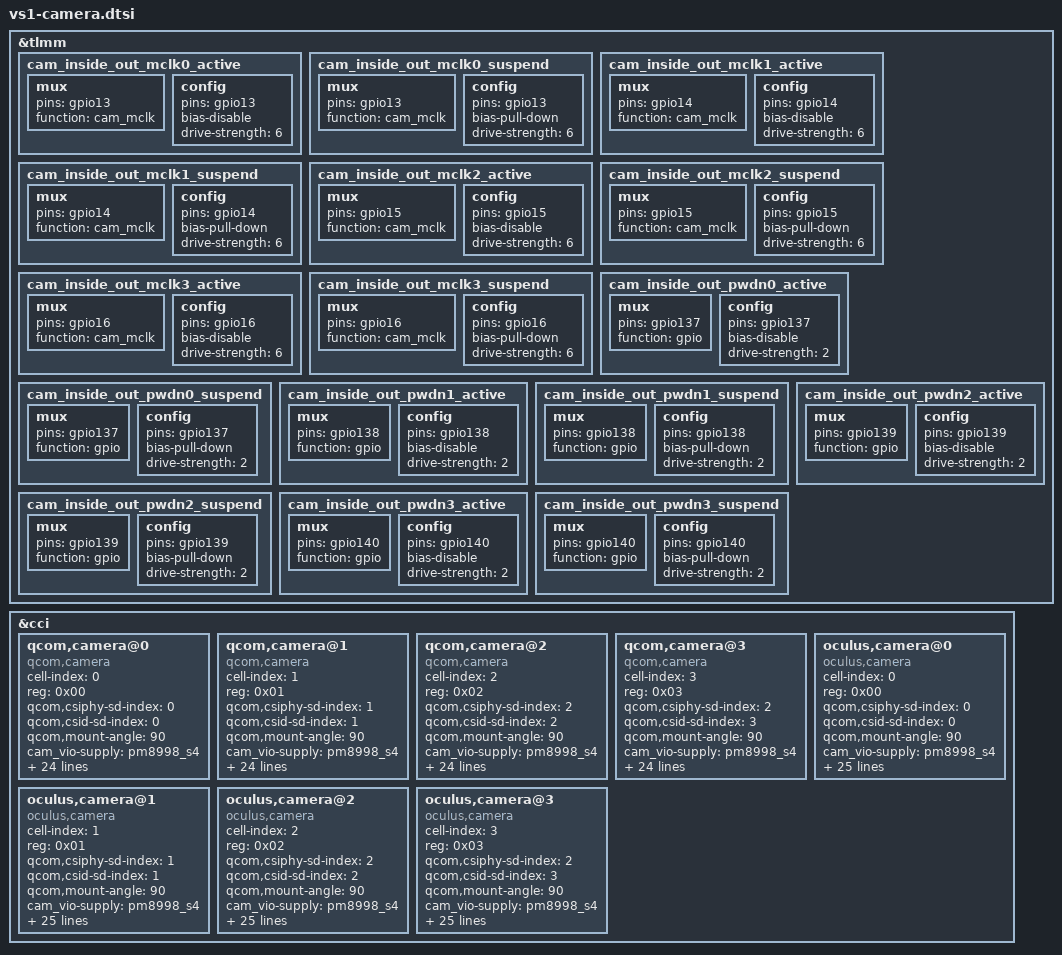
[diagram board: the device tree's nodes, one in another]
&tlmm {
	cam_inside_out_mclk0_active: cam_inside_out_mclk0_active {
		mux {
			pins = "gpio13";
			function = "cam_mclk";
		};
		config {
			pins = "gpio13";
			bias-disable;
			drive-strength = <6>;
		};
	};

	cam_inside_out_mclk0_suspend: cam_inside_out_mclk0_suspend {
		mux {
			pins = "gpio13";
			function = "cam_mclk";
		};
		config {
			pins = "gpio13";
			bias-pull-down;
			drive-strength = <6>;
		};
	};

	cam_inside_out_mclk1_active: cam_inside_out_mclk1_active {
		mux {
			pins = "gpio14";
			function = "cam_mclk";
		};
		config {
			pins = "gpio14";
			bias-disable;
			drive-strength = <6>;
		};
	};

	cam_inside_out_mclk1_suspend: cam_inside_out_mclk1_suspend {
		mux {
			pins = "gpio14";
			function = "cam_mclk";
		};
		config {
			pins = "gpio14";
			bias-pull-down;
			drive-strength = <6>;
		};
	};

	cam_inside_out_mclk2_active: cam_inside_out_mclk2_active {
		mux {
			pins = "gpio15";
			function = "cam_mclk";
		};
		config {
			pins = "gpio15";
			bias-disable;
			drive-strength = <6>;
		};
	};

	cam_inside_out_mclk2_suspend: cam_inside_out_mclk2_suspend {
		mux {
			pins = "gpio15";
			function = "cam_mclk";
		};
		config {
			pins = "gpio15";
			bias-pull-down;
			drive-strength = <6>;
		};
	};

	cam_inside_out_mclk3_active: cam_inside_out_mclk3_active {
		mux {
			pins = "gpio16";
			function = "cam_mclk";
		};
		config {
			pins = "gpio16";
			bias-disable;
			drive-strength = <6>;
		};
	};

	cam_inside_out_mclk3_suspend: cam_inside_out_mclk3_suspend {
		mux {
			pins = "gpio16";
			function = "cam_mclk";
		};
		config {
			pins = "gpio16";
			bias-pull-down;
			drive-strength = <6>;
		};
	};

	cam_inside_out_pwdn0_active: cam_inside_out_pwdn0_active {
		mux {
			pins = "gpio137";
			function = "gpio";
		};
		config {
			pins = "gpio137";
			bias-disable;
			drive-strength = <2>;
		};
	};

	cam_inside_out_pwdn0_suspend: cam_inside_out_pwdn0_suspend {
		mux {
			pins = "gpio137";
			function = "gpio";
		};
		config {
			pins = "gpio137";
			bias-pull-down;
			drive-strength = <2>;
		};
	};

	cam_inside_out_pwdn1_active: cam_inside_out_pwdn1_active {
		mux {
			pins = "gpio138";
			function = "gpio";
		};
		config {
			pins = "gpio138";
			bias-disable;
			drive-strength = <2>;
		};
	};

	cam_inside_out_pwdn1_suspend: cam_inside_out_pwdn1_suspend {
		mux {
			pins = "gpio138";
			function = "gpio";
		};
		config {
			pins = "gpio138";
			bias-pull-down;
			drive-strength = <2>;
		};
	};

	cam_inside_out_pwdn2_active: cam_inside_out_pwdn2_active {
		mux {
			pins = "gpio139";
			function = "gpio";
		};
		config {
			pins = "gpio139";
			bias-disable;
			drive-strength = <2>;
		};
	};

	cam_inside_out_pwdn2_suspend: cam_inside_out_pwdn2_suspend {
		mux {
			pins = "gpio139";
			function = "gpio";
		};
		config {
			pins = "gpio139";
			bias-pull-down;
			drive-strength = <2>;
		};
	};

	cam_inside_out_pwdn3_active: cam_inside_out_pwdn3_active {
		mux {
			pins = "gpio140";
			function = "gpio";
		};
		config {
			pins = "gpio140";
			bias-disable;
			drive-strength = <2>;
		};
	};

	cam_inside_out_pwdn3_suspend: cam_inside_out_pwdn3_suspend {
		mux {
			pins = "gpio140";
			function = "gpio";
		};
		config {
			pins = "gpio140";
			bias-pull-down;
			drive-strength = <2>;
		};
	};

};

&cci {
	/delete-node/ qcom,camera@0;
	/delete-node/ qcom,camera@1;
	/delete-node/ qcom,camera@2;
	/delete-node/ qcom,camera@3;

	qcom,camera@0 {
		status = "ok";
		cell-index = <0>;
		compatible = "qcom,camera";
		reg = <0x00>;
		qcom,csiphy-sd-index = <0>;
		qcom,csid-sd-index = <0>;
		qcom,mount-angle = <90>;
		cam_vio-supply = <&pm8998_s4>;
		cam_vana-supply = <&pm8998_l22>;
		cam_vdig-supply = <&pm8998_l14>;
		qcom,cam-vreg-name = "cam_vio", "cam_vana", "cam_vdig";
		qcom,cam-vreg-min-voltage = <0 2864000 1880000>;
		qcom,cam-vreg-max-voltage = <0 2864000 1880000>;
		qcom,cam-vreg-op-mode = <0 80000 105000>;
		qcom,gpio-no-mux = <0>;
		pinctrl-names = "cam_default", "cam_suspend";
		pinctrl-0 = <&cam_inside_out_mclk0_active
				&cam_inside_out_pwdn0_active>;
		pinctrl-1 = <&cam_inside_out_mclk0_suspend
				&cam_inside_out_pwdn0_suspend>;
		gpios = <&tlmm 13 0>,
			<&tlmm 137 0>;
		qcom,gpio-reset = <1>;
		qcom,gpio-req-tbl-num = <0 1>;
		qcom,gpio-req-tbl-flags = <1 0>;
		qcom,gpio-req-tbl-label = "CAMIF_MCLK0",
						"CAMIF_RESET0";
		qcom,sensor-position = <0>;
		qcom,sensor-mode = <0>;
		qcom,cci-master = <0>;
		clocks = <&clock_mmss clk_mclk0_clk_src>,
				<&clock_mmss clk_mmss_camss_mclk0_clk>;
		clock-names = "cam_src_clk", "cam_clk";
		qcom,clock-rates = <24000000 0>;
	};
	qcom,camera@1 {
		status = "ok";
		cell-index = <1>;
		compatible = "qcom,camera";
		reg = <0x01>;
		qcom,csiphy-sd-index = <1>;
		qcom,csid-sd-index = <1>;
		qcom,mount-angle = <90>;
		cam_vio-supply = <&pm8998_s4>;
		cam_vana-supply = <&pm8998_l22>;
		cam_vdig-supply = <&pm8998_l14>;
		qcom,cam-vreg-name = "cam_vio", "cam_vana", "cam_vdig";
		qcom,cam-vreg-min-voltage = <0 2864000 1880000>;
		qcom,cam-vreg-max-voltage = <0 2864000 1880000>;
		qcom,cam-vreg-op-mode = <0 80000 105000>;
		qcom,gpio-no-mux = <0>;
		pinctrl-names = "cam_default", "cam_suspend";
		pinctrl-0 = <&cam_inside_out_mclk1_active
				&cam_inside_out_pwdn1_active>;
		pinctrl-1 = <&cam_inside_out_mclk1_suspend
				&cam_inside_out_pwdn1_suspend>;
		gpios = <&tlmm 14 0>,
			<&tlmm 138 0>;
		qcom,gpio-reset = <1>;
		qcom,gpio-req-tbl-num = <0 1>;
		qcom,gpio-req-tbl-flags = <1 0>;
		qcom,gpio-req-tbl-label = "CAMIF_MCLK1",
						"CAMIF_RESET1";
		qcom,sensor-position = <1>;
		qcom,sensor-mode = <0>;
		qcom,cci-master = <0>;
		clocks = <&clock_mmss clk_mclk1_clk_src>,
				<&clock_mmss clk_mmss_camss_mclk1_clk>;
		clock-names = "cam_src_clk", "cam_clk";
		qcom,clock-rates = <24000000 0>;
	};
	qcom,camera@2 {
		status = "ok";
		cell-index = <2>;
		compatible = "qcom,camera";
		reg = <0x02>;
		qcom,csiphy-sd-index = <2>;
		qcom,csid-sd-index = <2>;
		qcom,mount-angle = <90>;
		cam_vio-supply = <&pm8998_s4>;
		cam_vana-supply = <&pm8998_l22>;
		cam_vdig-supply = <&pm8998_l14>;
		qcom,cam-vreg-name = "cam_vio", "cam_vana", "cam_vdig";
		qcom,cam-vreg-min-voltage = <0 2864000 1880000>;
		qcom,cam-vreg-max-voltage = <0 2864000 1880000>;
		qcom,cam-vreg-op-mode = <0 80000 105000>;
		qcom,gpio-no-mux = <0>;
		pinctrl-names = "cam_default", "cam_suspend";
		pinctrl-0 = <&cam_inside_out_mclk2_active
				&cam_inside_out_pwdn2_active>;
		pinctrl-1 = <&cam_inside_out_mclk2_suspend
				&cam_inside_out_pwdn2_suspend>;
		gpios = <&tlmm 15 0>,
			<&tlmm 139 0>;
		qcom,gpio-reset = <1>;
		qcom,gpio-req-tbl-num = <0 1>;
		qcom,gpio-req-tbl-flags = <1 0>;
		qcom,gpio-req-tbl-label = "CAMIF_MCLK2",
						"CAMIF_RESET2";
		qcom,sensor-position = <1>;
		qcom,sensor-mode = <0>;
		qcom,cci-master = <1>;
		clocks = <&clock_mmss clk_mclk2_clk_src>,
				<&clock_mmss clk_mmss_camss_mclk2_clk>;
		clock-names = "cam_src_clk", "cam_clk";
		qcom,clock-rates = <24000000 0>;
	};

	qcom,camera@3 {
		status = "ok";
		cell-index = <3>;
		compatible = "qcom,camera";
		reg = <0x03>;
		qcom,csiphy-sd-index = <2>;
		qcom,csid-sd-index = <3>;
		qcom,mount-angle = <90>;
		cam_vio-supply = <&pm8998_s4>;
		cam_vana-supply = <&pm8998_l22>;
		cam_vdig-supply = <&pm8998_l14>;
		qcom,cam-vreg-name = "cam_vio", "cam_vana", "cam_vdig";
		qcom,cam-vreg-min-voltage = <0 2864000 1880000>;
		qcom,cam-vreg-max-voltage = <0 2864000 1880000>;
		qcom,cam-vreg-op-mode = <0 80000 105000>;
		qcom,gpio-no-mux = <0>;
		pinctrl-names = "cam_default", "cam_suspend";
		pinctrl-0 = <&cam_inside_out_mclk3_active
				&cam_inside_out_pwdn3_active>;
		pinctrl-1 = <&cam_inside_out_mclk3_suspend
				&cam_inside_out_pwdn3_suspend>;
		gpios = <&tlmm 16 0>,
			<&tlmm 140 0>;
		qcom,gpio-reset = <1>;
		qcom,gpio-req-tbl-num = <0 1>;
		qcom,gpio-req-tbl-flags = <1 0>;
		qcom,gpio-req-tbl-label = "CAMIF_MCLK3",
						"CAMIF_RESET3";
		qcom,sensor-position = <0>;
		qcom,sensor-mode = <0>;
		qcom,cci-master = <1>;
		clocks = <&clock_mmss clk_mclk3_clk_src>,
				<&clock_mmss clk_mmss_camss_mclk3_clk>;
		clock-names = "cam_src_clk", "cam_clk";
		qcom,clock-rates = <24000000 0>;
	};

	oculus,camera@0 {
		status = "ok";
		cell-index = <0>;
		compatible = "oculus,camera";
		reg = <0x00>;
		qcom,csiphy-sd-index = <0>;
		qcom,csid-sd-index = <0>;
		qcom,mount-angle = <90>;
		cam_vio-supply = <&pm8998_s4>;
		cam_vana-supply = <&pm8998_l22>;
		cam_vdig-supply = <&pm8998_l14>;
		qcom,cam-vreg-name = "cam_vio", "cam_vana", "cam_vdig";
		qcom,cam-vreg-min-voltage = <0 2864000 1880000>;
		qcom,cam-vreg-max-voltage = <0 2864000 1880000>;
		qcom,cam-vreg-op-mode = <0 80000 105000>;
		qcom,gpio-no-mux = <0>;
		pinctrl-names = "cam_default", "cam_suspend";
		pinctrl-0 = <&cam_inside_out_mclk0_active
				&cam_inside_out_pwdn0_active>;
		pinctrl-1 = <&cam_inside_out_mclk0_suspend
				&cam_inside_out_pwdn0_suspend>;
		pwdn-gpios = <&tlmm 137 1>;
		gpios = <&tlmm 13 0>;
		qcom,gpio-reset = <1>;
		qcom,gpio-req-tbl-num = <0 1>;
		qcom,gpio-req-tbl-flags = <1 0>;
		qcom,gpio-req-tbl-label = "CAMIF_MCLK0",
						"CAMIF_RESET0";
		qcom,sensor-position = <0>;
		qcom,sensor-mode = <0>;
		qcom,cci-master = <0>;
		clocks = <&clock_mmss clk_mclk0_clk_src>,
				<&clock_mmss clk_mmss_camss_mclk0_clk>;
		clock-names = "cam_src_clk", "cam_clk";
		qcom,clock-rates = <24000000 0>;
	};
	oculus,camera@1 {
		status = "ok";
		cell-index = <1>;
		compatible = "oculus,camera";
		reg = <0x01>;
		qcom,csiphy-sd-index = <1>;
		qcom,csid-sd-index = <1>;
		qcom,mount-angle = <90>;
		cam_vio-supply = <&pm8998_s4>;
		cam_vana-supply = <&pm8998_l22>;
		cam_vdig-supply = <&pm8998_l14>;
		qcom,cam-vreg-name = "cam_vio", "cam_vana", "cam_vdig";
		qcom,cam-vreg-min-voltage = <0 2864000 1880000>;
		qcom,cam-vreg-max-voltage = <0 2864000 1880000>;
		qcom,cam-vreg-op-mode = <0 80000 105000>;
		qcom,gpio-no-mux = <0>;
		pinctrl-names = "cam_default", "cam_suspend";
		pinctrl-0 = <&cam_inside_out_mclk1_active
				&cam_inside_out_pwdn1_active>;
		pinctrl-1 = <&cam_inside_out_mclk1_suspend
				&cam_inside_out_pwdn1_suspend>;
		pwdn-gpios = <&tlmm 138 1>;
		gpios = <&tlmm 14 0>;
		qcom,gpio-reset = <1>;
		qcom,gpio-req-tbl-num = <0 1>;
		qcom,gpio-req-tbl-flags = <1 0>;
		qcom,gpio-req-tbl-label = "CAMIF_MCLK1",
						"CAMIF_RESET1";
		qcom,sensor-position = <1>;
		qcom,sensor-mode = <0>;
		qcom,cci-master = <0>;
		clocks = <&clock_mmss clk_mclk1_clk_src>,
				<&clock_mmss clk_mmss_camss_mclk1_clk>;
		clock-names = "cam_src_clk", "cam_clk";
		qcom,clock-rates = <24000000 0>;
	};
	oculus,camera@2 {
		status = "ok";
		cell-index = <2>;
		compatible = "oculus,camera";
		reg = <0x02>;
		qcom,csiphy-sd-index = <2>;
		qcom,csid-sd-index = <2>;
		qcom,mount-angle = <90>;
		cam_vio-supply = <&pm8998_s4>;
		cam_vana-supply = <&pm8998_l22>;
		cam_vdig-supply = <&pm8998_l14>;
		qcom,cam-vreg-name = "cam_vio", "cam_vana", "cam_vdig";
		qcom,cam-vreg-min-voltage = <0 2864000 1880000>;
		qcom,cam-vreg-max-voltage = <0 2864000 1880000>;
		qcom,cam-vreg-op-mode = <0 80000 105000>;
		qcom,gpio-no-mux = <0>;
		pinctrl-names = "cam_default", "cam_suspend";
		pinctrl-0 = <&cam_inside_out_mclk2_active
				&cam_inside_out_pwdn2_active>;
		pinctrl-1 = <&cam_inside_out_mclk2_suspend
				&cam_inside_out_pwdn2_suspend>;
		pwdn-gpios = <&tlmm 139 1>;
		gpios = <&tlmm 15 0>;
		qcom,gpio-reset = <1>;
		qcom,gpio-req-tbl-num = <0 1>;
		qcom,gpio-req-tbl-flags = <1 0>;
		qcom,gpio-req-tbl-label = "CAMIF_MCLK2",
						"CAMIF_RESET2";
		qcom,sensor-position = <1>;
		qcom,sensor-mode = <0>;
		qcom,cci-master = <1>;
		clocks = <&clock_mmss clk_mclk2_clk_src>,
				<&clock_mmss clk_mmss_camss_mclk2_clk>;
		clock-names = "cam_src_clk", "cam_clk";
		qcom,clock-rates = <24000000 0>;
	};

	oculus,camera@3 {
		status = "ok";
		cell-index = <3>;
		compatible = "oculus,camera";
		reg = <0x03>;
		qcom,csiphy-sd-index = <2>;
		qcom,csid-sd-index = <3>;
		qcom,mount-angle = <90>;
		cam_vio-supply = <&pm8998_s4>;
		cam_vana-supply = <&pm8998_l22>;
		cam_vdig-supply = <&pm8998_l14>;
		qcom,cam-vreg-name = "cam_vio", "cam_vana", "cam_vdig";
		qcom,cam-vreg-min-voltage = <0 2864000 1880000>;
		qcom,cam-vreg-max-voltage = <0 2864000 1880000>;
		qcom,cam-vreg-op-mode = <0 80000 105000>;
		qcom,gpio-no-mux = <0>;
		pinctrl-names = "cam_default", "cam_suspend";
		pinctrl-0 = <&cam_inside_out_mclk3_active
				&cam_inside_out_pwdn3_active>;
		pinctrl-1 = <&cam_inside_out_mclk3_suspend
				&cam_inside_out_pwdn3_suspend>;
		pwdn-gpios = <&tlmm 140 1>;
		gpios = <&tlmm 16 0>;
		qcom,gpio-reset = <1>;
		qcom,gpio-req-tbl-num = <0 1>;
		qcom,gpio-req-tbl-flags = <1 0>;
		qcom,gpio-req-tbl-label = "CAMIF_MCLK3",
						"CAMIF_RESET3";
		qcom,sensor-position = <0>;
		qcom,sensor-mode = <0>;
		qcom,cci-master = <1>;
		clocks = <&clock_mmss clk_mclk3_clk_src>,
				<&clock_mmss clk_mmss_camss_mclk3_clk>;
		clock-names = "cam_src_clk", "cam_clk";
		qcom,clock-rates = <24000000 0>;
	};
};
